# PIC32MK1024GPL100 register map
Vendor: Microchip
Registers are 32-bit, read-write, no defined reset value unless marked. A register's access mark holds for its fields unless they carry their own. Addresses are absolute, and some are shared; only a register's first bit layout is shown; [hi:lo] are bit positions; {n}, {i} and the like mark numbered series; 'fields as' and 'values as' point back to an identical list.

## PORTG
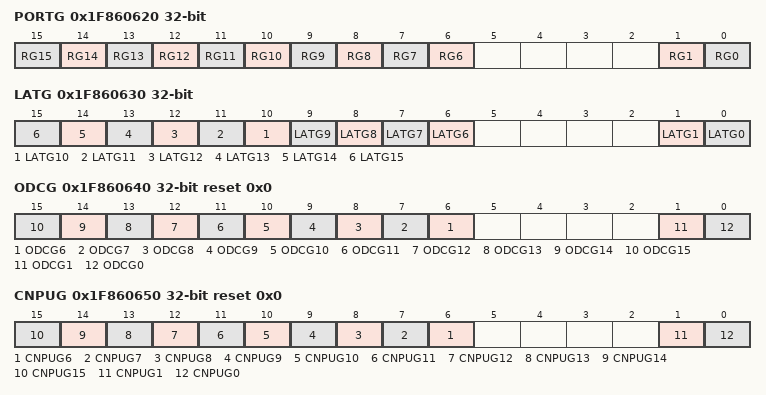
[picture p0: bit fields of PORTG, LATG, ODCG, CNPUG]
0x1F860620 PORTG — (power-on value ----------------xxxxxxxxxx----xx)
  [n] RG{n} (n=6..15), [1] RG1, [0] RG0
0x1F860630 LATG — (power-on value ----------------xxxxxxxxxx----xx)
  [n] LATG{n} (n=6..15), [1] LATG1, [0] LATG0
0x1F860640 ODCG reset 0x0
  [n] ODCG{n} (n=6..15), [1] ODCG1, [0] ODCG0
0x1F860650 CNPUG reset 0x0
  [n] CNPUG{n} (n=6..15), [1] CNPUG1, [0] CNPUG0
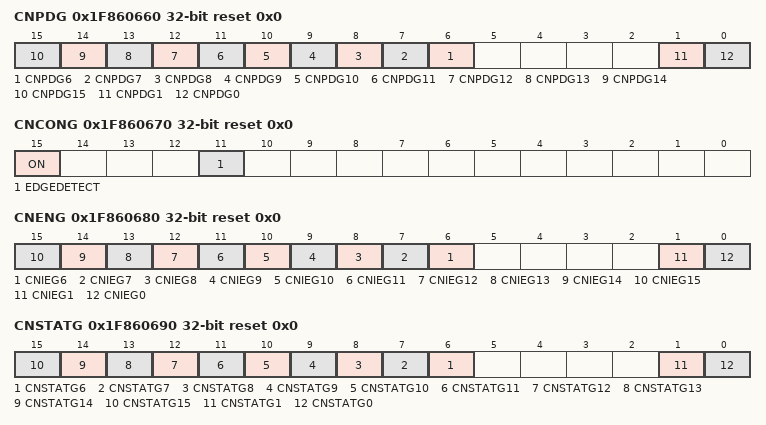
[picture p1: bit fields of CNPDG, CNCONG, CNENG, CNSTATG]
0x1F860660 CNPDG reset 0x0
  [n] CNPDG{n} (n=6..15), [1] CNPDG1, [0] CNPDG0
0x1F860670 CNCONG reset 0x0
  [15] ON, [11] EDGEDETECT
0x1F860680 CNENG reset 0x0
  [n] CNIEG{n} (n=6..15), [1] CNIEG1, [0] CNIEG0
0x1F860690 CNSTATG reset 0x0
  [n] CNSTATG{n} (n=6..15), [1] CNSTATG1, [0] CNSTATG0
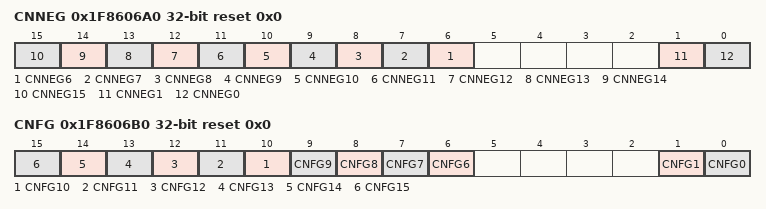
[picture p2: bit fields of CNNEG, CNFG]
0x1F8606A0 CNNEG reset 0x0
  [n] CNNEG{n} (n=6..15), [1] CNNEG1, [0] CNNEG0
0x1F8606B0 CNFG reset 0x0
  [n] CNFG{n} (n=6..15), [1] CNFG1, [0] CNFG0

## adc_sar_ctrl_upb
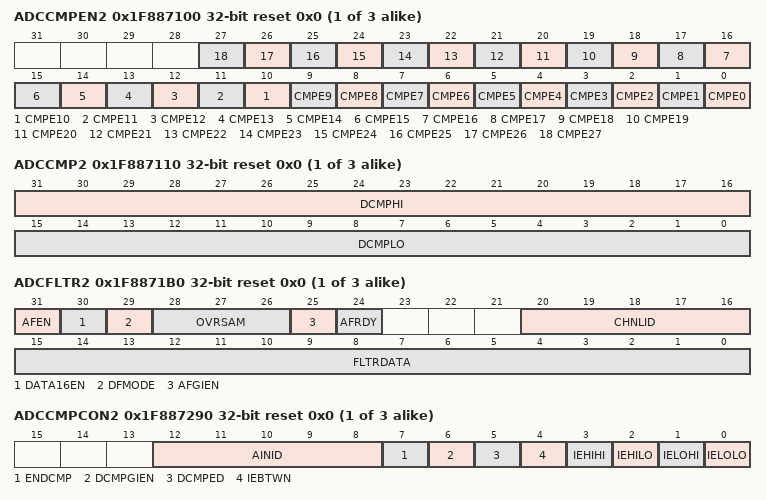
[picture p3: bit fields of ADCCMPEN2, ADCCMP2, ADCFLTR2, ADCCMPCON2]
{0x1F8870C0+0x20*i} ADCCMPEN{i} reset 0x0 (i=2..4)
  [n] CMPE{n} (n=0..27)
{0x1F8870D0+0x20*i} ADCCMP{i} reset 0x0 (i=2..4)
  [31:16] DCMPHI, [15:0] DCMPLO
{0x1F887190+0x10*i} ADCFLTR{i} reset 0x0 (i=2..4)
  [31] AFEN, [30] DATA16EN, [29] DFMODE, [28:26] OVRSAM, [25] AFGIEN, [24] AFRDY ro, [20:16] CHNLID, [15:0] FLTRDATA ro
{0x1F887270+0x10*i} ADCCMPCON{i} reset 0x0 (i=2..4)
  [12:8] AINID ro, [7] ENDCMP, [6] DCMPGIEN, [5] DCMPED ro, [4] IEBTWN, [3] IEHIHI, [2] IEHILO, [1] IELOHI, [0] IELOLO
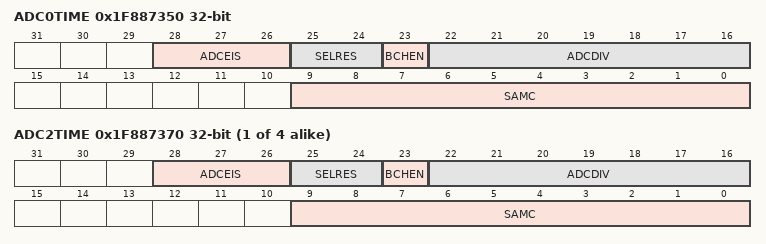
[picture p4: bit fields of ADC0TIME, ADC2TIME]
0x1F887350 ADC0TIME — (power-on value ---00000x0000000------0000000000)
  [28:26] ADCEIS, [25:24] SELRES, [23] BCHEN, [22:16] ADCDIV, [9:0] SAMC
{0x1F887350+0x10*i} ADC{i}TIME (i=2..5) — (power-on value ---00000x0000000------0000000000)
  fields as ADC0TIME

## USB1
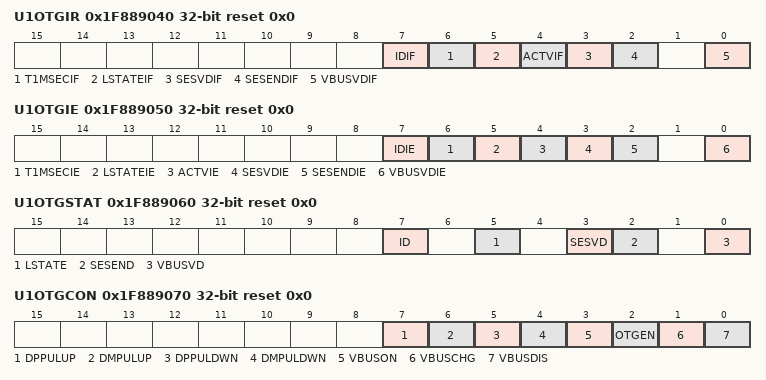
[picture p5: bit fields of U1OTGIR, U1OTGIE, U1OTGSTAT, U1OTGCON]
0x1F889040 U1OTGIR reset 0x0
  [7] IDIF, [6] T1MSECIF, [5] LSTATEIF, [4] ACTVIF, [3] SESVDIF, [2] SESENDIF, [0] VBUSVDIF
0x1F889050 U1OTGIE reset 0x0
  [7] IDIE, [6] T1MSECIE, [5] LSTATEIE, [4] ACTVIE, [3] SESVDIE, [2] SESENDIE, [0] VBUSVDIE
0x1F889060 U1OTGSTAT reset 0x0
  [7] ID, [5] LSTATE, [3] SESVD, [2] SESEND, [0] VBUSVD
0x1F889070 U1OTGCON reset 0x0
  [7] DPPULUP, [6] DMPULUP, [5] DPPULDWN, [4] DMPULDWN, [3] VBUSON, [2] OTGEN, [1] VBUSCHG, [0] VBUSDIS
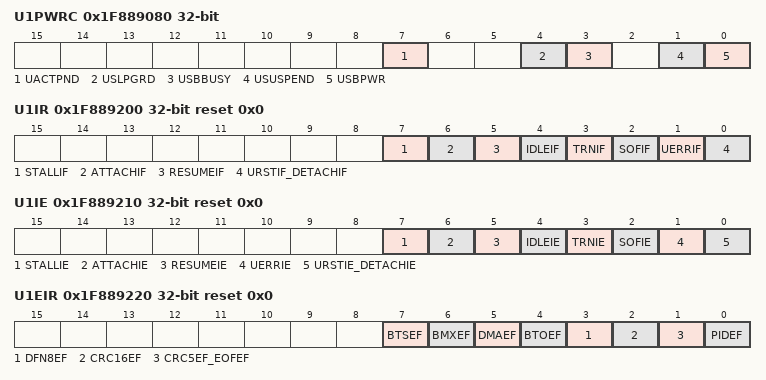
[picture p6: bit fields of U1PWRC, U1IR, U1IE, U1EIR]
0x1F889080 U1PWRC — (power-on value ------------------------0--0x-00)
  [7] UACTPND ro, [4] USLPGRD, [3] USBBUSY, [1] USUSPEND, [0] USBPWR
0x1F889200 U1IR reset 0x0
  [7] STALLIF, [6] ATTACHIF, [5] RESUMEIF, [4] IDLEIF, [3] TRNIF, [2] SOFIF, [1] UERRIF, [0] URSTIF_DETACHIF
0x1F889210 U1IE reset 0x0
  [7] STALLIE, [6] ATTACHIE, [5] RESUMEIE, [4] IDLEIE, [3] TRNIE, [2] SOFIE, [1] UERRIE, [0] URSTIE_DETACHIE
0x1F889220 U1EIR reset 0x0
  [7] BTSEF, [6] BMXEF, [5] DMAEF, [4] BTOEF, [3] DFN8EF, [2] CRC16EF, [1] CRC5EF_EOFEF, [0] PIDEF
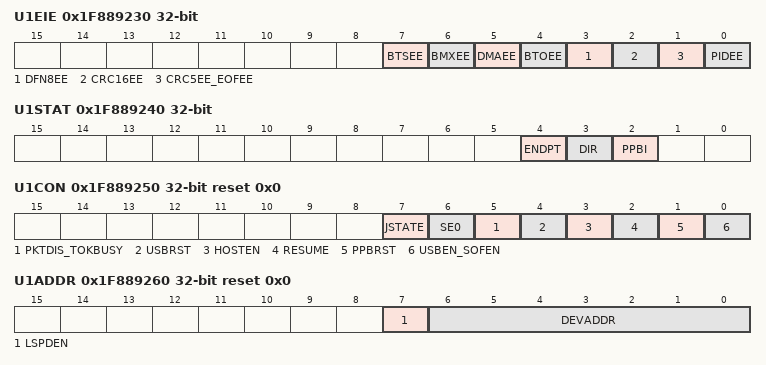
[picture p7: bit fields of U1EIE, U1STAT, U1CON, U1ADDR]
0x1F889230 U1EIE — (power-on value ------------------------0000000x)
  [7] BTSEE, [6] BMXEE, [5] DMAEE, [4] BTOEE, [3] DFN8EE, [2] CRC16EE, [1] CRC5EE_EOFEE, [0] PIDEE
0x1F889240 U1STAT ro
  [4] ENDPT, [3] DIR, [2] PPBI
0x1F889250 U1CON reset 0x0
  [7] JSTATE, [6] SE0, [5] PKTDIS_TOKBUSY, [4] USBRST, [3] HOSTEN, [2] RESUME, [1] PPBRST, [0] USBEN_SOFEN
0x1F889260 U1ADDR reset 0x0
  [7] LSPDEN, [6:0] DEVADDR
0x1F889270 U1BDTP1 reset 0x0
  [7:1] BDTPTRL
0x1F889280 U1FRML ro
  [7:0] FRML
0x1F889290 U1FRMH ro
  [2:0] FRMH
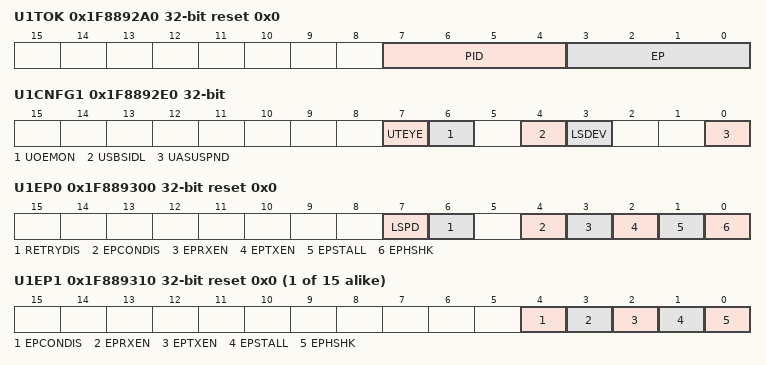
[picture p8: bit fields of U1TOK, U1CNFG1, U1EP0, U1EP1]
0x1F8892A0 U1TOK reset 0x0
  [7:4] PID, [3:0] EP
0x1F8892B0 U1SOF reset 0x0
  [7:0] CNT
0x1F8892C0 U1BDTP2 reset 0x0
  [7:0] BDTPTRH
0x1F8892D0 U1BDTP3 reset 0x0
  [7:0] BDTPTRU
0x1F8892E0 U1CNFG1 — (power-on value ------------------------xxxxx00x)
  [7] UTEYE, [6] UOEMON, [4] USBSIDL, [3] LSDEV, [0] UASUSPND
0x1F889300 U1EP0 reset 0x0
  [7] LSPD, [6] RETRYDIS, [4] EPCONDIS, [3] EPRXEN, [2] EPTXEN, [1] EPSTALL, [0] EPHSHK
{0x1F889300+0x10*i} U1EP{i} reset 0x0 (i=1..15)
  [4] EPCONDIS, [3] EPRXEN, [2] EPTXEN, [1] EPSTALL, [0] EPHSHK
